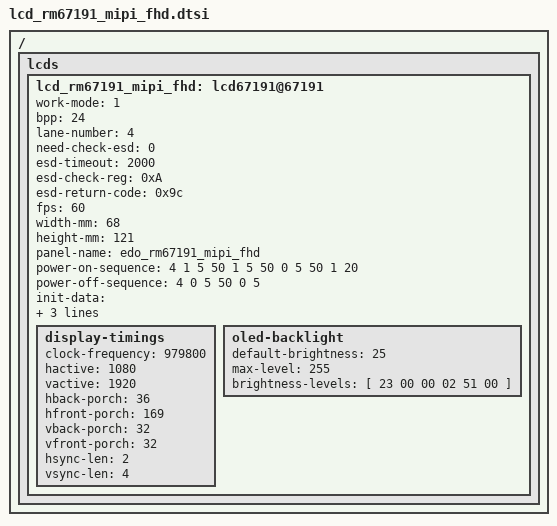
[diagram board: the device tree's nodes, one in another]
/ { lcds {
	lcd_rm67191_mipi_fhd: lcd67191@67191 {

		work-mode = <1>;
		bpp = <24>;
		lane-number = <4>;

		need-check-esd = <0>;
		esd-timeout = <2000>;
		esd-check-reg = <0xA>;
		esd-return-code = <0x9c>;

		fps = <60>;
		width-mm = <68>;
		height-mm = <121>;
		panel-name = "edo_rm67191_mipi_fhd";

		power-on-sequence = <
					4  1  5
					50  1  5
					50  0  5
					50  1  20
					>;
		power-off-sequence = <
					4  0  5
					50  0  5
					>;

		init-data = [
			23 00 00 02 FE 0E
			23 00 00 02 4B 00
			23 00 00 02 4C 0F
			23 00 00 02 4D 20
			23 00 00 02 4E 40
			23 00 00 02 4F 60
			23 00 00 02 50 A0
			23 00 00 02 51 C0
			23 00 00 02 52 E0
			23 00 00 02 53 FF

			23 00 00 02 FE 0D
			23 00 00 02 08 41
			23 00 00 02 46 02
			23 00 00 02 72 09
			23 00 00 02 1E 04
			23 00 00 02 1E 00

			23 00 00 02 FE 0A
			23 00 00 02 24 17
			23 00 00 02 04 07
			23 00 00 02 1A 0C

			23 00 00 02 FE 04
			23 00 00 02 00 0C
			23 00 00 02 05 10
			23 00 00 02 06 08
			23 00 00 02 08 10
			23 00 00 02 09 08
			23 00 00 02 0A E6
			23 00 00 02 0B 8C
			23 00 00 02 1A 12
//			23 00 00 02 1E E0
			23 00 00 02 29 93
			23 00 00 02 2A 93
			23 00 00 02 2F 02
			23 00 00 02 31 02
			23 00 00 02 33 05
			23 00 00 02 37 2D
			23 00 00 02 38 2D
			23 00 00 02 3A 1E
			23 00 00 02 3B 1E
			23 00 00 02 3D 27
			23 00 00 02 3F 80
			23 00 00 02 40 40
			23 00 00 02 41 E0
			23 00 00 02 4F 2F
			23 00 00 02 50 1E

			23 00 00 02 FE 06
			23 00 00 02 00 EC
			23 00 00 02 05 06
			23 00 00 02 07 A2
			23 00 00 02 08 EC
			23 00 00 02 0D 04
			23 00 00 02 0F A2
			23 00 00 02 32 EC
			23 00 00 02 37 07
			23 00 00 02 39 83
			23 00 00 02 3A EC
			23 00 00 02 41 06
			23 00 00 02 43 83
			23 00 00 02 44 EC
			23 00 00 02 49 06
			23 00 00 02 4B A2
			23 00 00 02 4C EC
			23 00 00 02 51 04
			23 00 00 02 53 A2
			23 00 00 02 75 EC
			23 00 00 02 7A 07
			23 00 00 02 7C 83
			23 00 00 02 7D EC
			23 00 00 02 82 06
			23 00 00 02 84 83
			23 00 00 02 85 EC
			23 00 00 02 86 0F
			23 00 00 02 87 FF
			23 00 00 02 88 00
			23 00 00 02 8A 02
			23 00 00 02 8C A2
			23 00 00 02 8D EE
			23 00 00 02 8E 01
			23 00 00 02 8F E8
			23 00 00 02 90 0A
			23 00 00 02 92 06
			23 00 00 02 93 A0
			23 00 00 02 94 A8
			23 00 00 02 95 EC
			23 00 00 02 96 0F
			23 00 00 02 97 FF
			23 00 00 02 98 00
			23 00 00 02 9A 02
			23 00 00 02 9C A2
			23 00 00 02 A6 21
			23 00 00 02 A7 05
			23 00 00 02 A9 06
			23 00 00 02 AC 04
			23 00 00 02 B1 12
			23 00 00 02 B2 17
			23 00 00 02 B3 17
			23 00 00 02 B4 17
			23 00 00 02 B5 17
			23 00 00 02 B6 11
			23 00 00 02 B7 08
			23 00 00 02 B8 09
			23 00 00 02 B9 06
			23 00 00 02 BA 07
			23 00 00 02 BB 17
			23 00 00 02 BC 17
			23 00 00 02 BD 17
			23 00 00 02 BE 17
			23 00 00 02 BF 17
			23 00 00 02 C0 17
			23 00 00 02 C1 17
			23 00 00 02 C2 17
			23 00 00 02 C3 17
			23 00 00 02 C4 0F
			23 00 00 02 C5 0E
			23 00 00 02 C6 00
			23 00 00 02 C7 01
			23 00 00 02 C8 10

			23 00 00 02 FE 00
			23 00 00 02 51 00
			23 00 00 02 C2 03
			23 00 00 02 35 00
			29 00 00 03 44 03 80
			13 78 00 01 11
			13 64 00 01 29
			];
		sleep-in =  [
			13 0A 00 01 28
			13 78 00 01 10
			];
		sleep-out = [
			13 78 00 01 11
			13 64 00 01 29
			];

		display-timings {
			clock-frequency = <979800>;
			hactive = <1080>;
			vactive = <1920>;
			hback-porch = <36>;
			hfront-porch = <169>;
			vback-porch = <32>;
			vfront-porch = <32>;
			hsync-len = <2>;
			vsync-len = <4>;
		};
		oled-backlight {
			default-brightness = <25>;
			max-level = <255>;
			brightness-levels = [
				23 00 00 02 51 00
			];
		};
	};
};};
